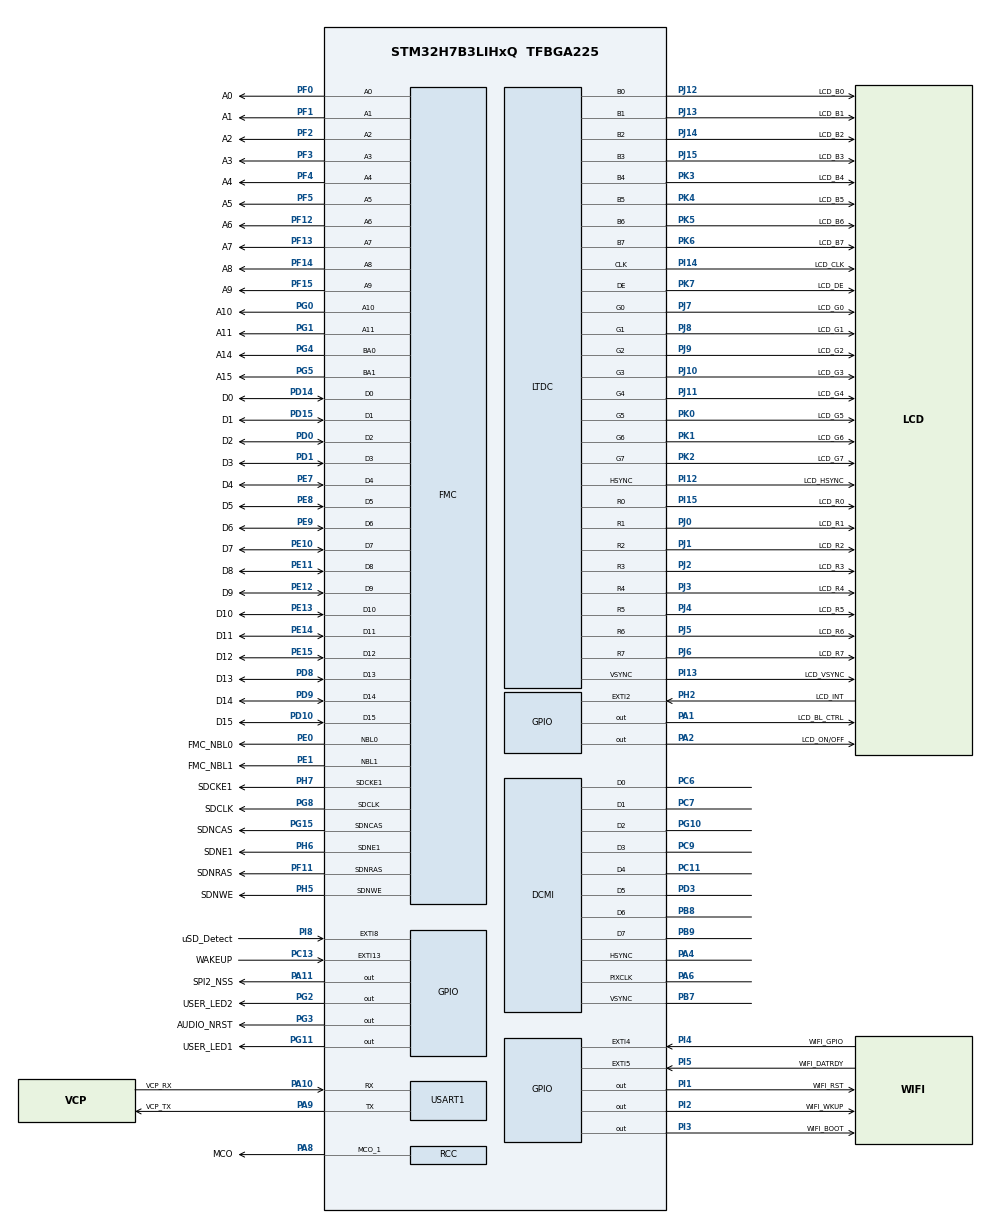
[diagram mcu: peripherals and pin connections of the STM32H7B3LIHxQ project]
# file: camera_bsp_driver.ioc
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CORTEX_M7.CPU_DCache=Enabled
CORTEX_M7.CPU_ICache=Enabled
DCMI.HSPolarity=DCMI_HSPOLARITY_HIGH
DCMI.PCKPolarity=DCMI_PCKPOLARITY_RISING
DCMI.VSPolarity=DCMI_VSPOLARITY_HIGH
DMA2D.ColorMode=DMA2D_OUTPUT_ARGB8888
DMA2D.InputColorModeForeground=DMA2D_INPUT_RGB565
DMA2D.Mode=DMA2D_M2M_PFC
Dma.DCMI.0.Direction=DMA_PERIPH_TO_MEMORY
Dma.DCMI.0.EventEnable=DISABLE
Dma.DCMI.0.FIFOMode=DMA_FIFOMODE_DISABLE
Dma.DCMI.0.Instance=DMA2_Stream1
Dma.DCMI.0.MemDataAlignment=DMA_MDATAALIGN_WORD
Dma.DCMI.0.MemInc=DMA_MINC_ENABLE
Dma.DCMI.0.Mode=DMA_NORMAL
Dma.DCMI.0.PeriphDataAlignment=DMA_PDATAALIGN_WORD
Dma.DCMI.0.PeriphInc=DMA_PINC_DISABLE
Dma.DCMI.0.Polarity=HAL_DMAMUX_REQ_GEN_RISING
Dma.DCMI.0.Priority=DMA_PRIORITY_HIGH
Dma.DCMI.0.RequestNumber=1
Dma.DCMI.0.SignalID=NONE
Dma.DCMI.0.SyncEnable=DISABLE
Dma.DCMI.0.SyncPolarity=HAL_DMAMUX_SYNC_NO_EVENT
Dma.DCMI.0.SyncRequestNumber=1
Dma.DCMI.0.SyncSignalID=NONE
Dma.Request0=DCMI
FMC.CASLatency2=FMC_SDRAM_CAS_LATENCY_2
FMC.ColumnBitsNumber2=FMC_SDRAM_COLUMN_BITS_NUM_9
FMC.ExitSelfRefreshDelay2=7
FMC.LoadToActiveDelay2=2
FMC.RCDDelay2=2
FMC.RPDelay1=2
FMC.RPDelay2=2
FMC.ReadBurst1=FMC_SDRAM_RBURST_ENABLE
FMC.ReadBurst2=FMC_SDRAM_RBURST_ENABLE
FMC.ReadPipeDelay1=FMC_SDRAM_RPIPE_DELAY_2
FMC.ReadPipeDelay2=FMC_SDRAM_RPIPE_DELAY_2
FMC.RowCycleDelay1=6
FMC.RowCycleDelay2=6
FMC.SDClockPeriod1=FMC_SDRAM_CLOCK_PERIOD_2
FMC.SDClockPeriod2=FMC_SDRAM_CLOCK_PERIOD_2
FMC.SelfRefreshTime2=5
FMC.WriteRecoveryTime2=3
LTDC.Alpha_L0=0
LTDC.Blue_L0=0
LTDC.DEPolarity=LTDC_DEPOLARITY_AH
LTDC.FBStartAdress_L0=0
LTDC.ImageHeight_L0=0
LTDC.ImageWidth_L0=0
LTDC.Layers=0
LTDC.PixelFormat_L0=LTDC_PIXEL_FORMAT_ARGB8888
LTDC.WindowX0_L0=0
LTDC.WindowX1_L0=0
LTDC.WindowY0_L0=0
LTDC.WindowY1_L0=0
Mcu.Family=STM32H7
Mcu.Name=STM32H7B3LIHxQ
Mcu.Package=TFBGA225
NVIC.DCMI_PSSI_IRQn=true\:0\:0\:false\:false\:true\:true\:true\:true
NVIC.DMA2D_IRQn=true\:0\:0\:false\:false\:true\:true\:true\:true
NVIC.DMA2_Stream1_IRQn=true\:0\:0\:false\:false\:true\:false\:true\:true
NVIC.LTDC_ER_IRQn=true\:0\:0\:false\:false\:true\:true\:true\:true
NVIC.LTDC_IRQn=true\:0\:0\:false\:false\:true\:true\:true\:true
NVIC.PriorityGroup=NVIC_PRIORITYGROUP_4
NVIC.USART1_IRQn=true\:0\:0\:false\:false\:true\:true\:true\:true
PA0.GPIO_Label=I2S6_WS
PA0.Signal=I2S6_WS
PA1.GPIO_Label=LCD_BL_CTRL
PA1.PinState=GPIO_PIN_SET
PA1.Signal=GPIO_Output
PA10.GPIO_Label=VCP_RX
PA10.Mode=Asynchronous
PA10.Signal=USART1_RX
PA11.GPIO_Label=SPI2_NSS
PA11.Signal=GPIO_Output
PA12.GPIO_Label=SPI2_SCK
PA12.Signal=SPI2_SCK
PA13.GPIO_Label=JTMS
PA13.Mode=JTAG_5_pins
PA13.Signal=DEBUG_JTMS-SWDIO
PA14.GPIO_Label=JTCK
PA14.Mode=JTAG_5_pins
PA14.Signal=DEBUG_JTCK-SWCLK
PA15.GPIO_Label=JTDI
PA15.Mode=JTAG_5_pins
PA15.Signal=DEBUG_JTDI
PA2.GPIO_Label=LCD_ON/OFF
PA2.PinState=GPIO_PIN_SET
PA2.Signal=GPIO_Output
PA3.GPIO_Label=I2S6_MCK
PA3.Signal=I2S6_MCK
PA4.Mode=Slave_8_bits_External_Synchro
PA4.Signal=DCMI_HSYNC
PA6.Mode=Slave_8_bits_External_Synchro
PA6.Signal=DCMI_PIXCLK
PA8.GPIO_Label=MCO
PA8.Mode=Clock-out-1
PA8.Signal=RCC_MCO_1
PA9.GPIO_Label=VCP_TX
PA9.Mode=Asynchronous
PA9.Signal=USART1_TX
PB2.GPIO_Label=OCSPI1_CLK
PB2.Signal=OCTOSPIM_P1_CLK
PB3.GPIO_Label=JTDO_TRACESWO
PB3.Mode=JTAG_5_pins
PB3.Signal=DEBUG_JTDO-SWO
PB4.Mode=JTAG_5_pins
PB4.Signal=DEBUG_JTRST
PB7.Mode=Slave_8_bits_External_Synchro
PB7.Signal=DCMI_VSYNC
PB8.Mode=Slave_8_bits_External_Synchro
PB8.Signal=DCMI_D6
PB9.Mode=Slave_8_bits_External_Synchro
PB9.Signal=DCMI_D7
PC1.GPIO_Label=OCSPI1_IO4
PC1.Signal=OCTOSPIM_P1_IO4
PC10.GPIO_Label=SDIO1_D2
PC10.Signal=SDMMC1_D2
PC11.Mode=Slave_8_bits_External_Synchro
PC11.Signal=DCMI_D4
PC12.GPIO_Label=SDIO1_CK
PC12.Signal=SDMMC1_CK
PC13.GPIO_Label=WAKEUP
PC13.Signal=GPXTI13
PC14-OSC32_IN.Mode=LSE-External-Oscillator
PC14-OSC32_IN.Signal=RCC_OSC32_IN
PC15-OSC32_OUT.Mode=LSE-External-Oscillator
PC15-OSC32_OUT.Signal=RCC_OSC32_OUT
PC2.GPIO_Label=SPI2_MISO
PC2.Signal=SPI2_MISO
PC3.GPIO_Label=SPI2_MOSI
PC3.Signal=SPI2_MOSI
PC5.GPIO_Label=OCSPI1_DQS
PC5.Signal=OCTOSPIM_P1_DQS
PC6.Mode=Slave_8_bits_External_Synchro
PC6.Signal=DCMI_D0
PC7.Mode=Slave_8_bits_External_Synchro
PC7.Signal=DCMI_D1
PC8.GPIO_Label=SDIO1_D0
PC8.Signal=SDMMC1_D0
PC9.Mode=Slave_8_bits_External_Synchro
PC9.Signal=DCMI_D3
PD0.GPIO_Label=D2
PD0.Signal=FMC_D2_DA2
PD1.GPIO_Label=D3
PD1.Signal=FMC_D3_DA3
PD10.GPIO_Label=D15
PD10.Signal=FMC_D15_DA15
PD12.GPIO_Label=I2C4_SCL
PD12.GPIO_Pu=GPIO_PULLUP
PD12.Signal=I2C4_SCL
PD13.GPIO_Label=I2C4_SDA
PD13.GPIO_Pu=GPIO_PULLUP
PD13.Signal=I2C4_SDA
PD14.GPIO_Label=D0
PD14.Signal=FMC_D0_DA0
PD15.GPIO_Label=D1
PD15.Signal=FMC_D1_DA1
PD2.GPIO_Label=SDIO1_CMD
PD2.Signal=SDMMC1_CMD
PD3.Mode=Slave_8_bits_External_Synchro
PD3.Signal=DCMI_D5
PD7.GPIO_Label=OCSPI1_IO7
PD7.Signal=OCTOSPIM_P1_IO7
PD8.GPIO_Label=D13
PD8.Signal=FMC_D13_DA13
PD9.GPIO_Label=D14
PD9.Signal=FMC_D14_DA14
PE0.GPIO_Label=FMC_NBL0
PE0.Signal=FMC_NBL0
PE1.GPIO_Label=FMC_NBL1
PE1.Signal=FMC_NBL1
PE10.GPIO_Label=D7
PE10.Signal=FMC_D7_DA7
PE11.GPIO_Label=D8
PE11.Signal=FMC_D8_DA8
PE12.GPIO_Label=D9
PE12.Signal=FMC_D9_DA9
PE13.GPIO_Label=D10
PE13.Signal=FMC_D10_DA10
PE14.GPIO_Label=D11
PE14.Signal=FMC_D11_DA11
PE15.GPIO_Label=D12
PE15.Signal=FMC_D12_DA12
PE7.GPIO_Label=D4
PE7.Signal=FMC_D4_DA4
PE8.GPIO_Label=D5
PE8.Signal=FMC_D5_DA5
PE9.GPIO_Label=D6
PE9.Signal=FMC_D6_DA6
PF0.GPIO_Label=A0
PF0.Signal=FMC_A0
PF1.GPIO_Label=A1
PF1.Signal=FMC_A1
PF11.GPIO_Label=SDNRAS
PF11.Signal=FMC_SDNRAS
PF12.GPIO_Label=A6
PF12.Signal=FMC_A6
PF13.GPIO_Label=A7
PF13.Signal=FMC_A7
PF14.GPIO_Label=A8
PF14.Signal=FMC_A8
PF15.GPIO_Label=A9
PF15.Signal=FMC_A9
PF2.GPIO_Label=A2
PF2.Signal=FMC_A2
PF3.GPIO_Label=A3
PF3.Signal=FMC_A3
PF4.GPIO_Label=A4
PF4.Signal=FMC_A4
PF5.GPIO_Label=A5
PF5.Signal=FMC_A5
PG0.GPIO_Label=A10
PG0.Signal=FMC_A10
PG1.GPIO_Label=A11
PG1.Signal=FMC_A11
PG10.Mode=Slave_8_bits_External_Synchro
PG10.Signal=DCMI_D2
PG11.GPIO_Label=USER_LED1
PG11.Signal=GPIO_Output
PG12.GPIO_Label=I2S6_SDI
PG12.Signal=I2S6_SDI
PG13.GPIO_Label=I2S6_CK
PG13.Signal=I2S6_CK
PG14.GPIO_Label=I2S6_SDO
PG14.Signal=I2S6_SDO
PG15.GPIO_Label=SDNCAS
PG15.Signal=FMC_SDNCAS
PG2.GPIO_Label=USER_LED2
PG2.Signal=GPIO_Output
PG3.GPIO_Label=AUDIO_NRST
PG3.PinState=GPIO_PIN_SET
PG3.Signal=GPIO_Output
PG4.GPIO_Label=A14
PG4.Signal=FMC_A14_BA0
PG5.GPIO_Label=A15
PG5.Signal=FMC_A15_BA1
PG6.GPIO_Label=OCSPI1_NCS
PG6.Signal=OCTOSPIM_P1_NCS
PG8.GPIO_Label=SDCLK
PG8.Signal=FMC_SDCLK
PG9.GPIO_Label=OCSPI1_IO6
PG9.Signal=OCTOSPIM_P1_IO6
PH0-OSC_IN.Mode=HSE-External-Oscillator
PH0-OSC_IN.Signal=RCC_OSC_IN
PH1-OSC_OUT.Mode=HSE-External-Oscillator
PH1-OSC_OUT.Signal=RCC_OSC_OUT
PH2.GPIO_Label=LCD_INT
PH2.Signal=GPXTI2
PH3.GPIO_Label=OCSPI1_IO5
PH3.Signal=OCTOSPIM_P1_IO5
PH5.GPIO_Label=SDNWE
PH5.Signal=FMC_SDNWE
PH6.GPIO_Label=SDNE1
PH6.Mode=SdramChipSelect2_2
PH6.Signal=FMC_SDNE1
PH7.GPIO_Label=SDCKE1
PH7.Mode=SdramChipSelect2_2
PH7.Signal=FMC_SDCKE1
PI1.GPIO_Label=WIFI_RST
PI1.Signal=GPIO_Output
PI12.GPIO_Label=LCD_HSYNC
PI12.GPIO_Speed=GPIO_SPEED_FREQ_VERY_HIGH
PI12.Mode=RGB888
PI12.Signal=LTDC_HSYNC
PI13.GPIO_Label=LCD_VSYNC
PI13.GPIO_Speed=GPIO_SPEED_FREQ_VERY_HIGH
PI13.Mode=RGB888
PI13.Signal=LTDC_VSYNC
PI14.GPIO_Label=LCD_CLK
PI14.GPIO_Speed=GPIO_SPEED_FREQ_VERY_HIGH
PI14.Mode=RGB888
PI14.Signal=LTDC_CLK
PI15.GPIO_Label=LCD_R0
PI15.GPIO_Speed=GPIO_SPEED_FREQ_VERY_HIGH
PI15.Mode=RGB888
PI15.Signal=LTDC_R0
PI2.GPIO_Label=WIFI_WKUP
PI2.Signal=GPIO_Output
PI3.GPIO_Label=WIFI_BOOT
PI3.Signal=GPIO_Output
PI4.GPIO_Label=WIFI_GPIO
PI4.Signal=GPXTI4
PI5.GPIO_Label=WIFI_DATRDY
PI5.Signal=GPXTI5
PI8.GPIO_Label=uSD_Detect
PI8.GPIO_PuPd=GPIO_PULLUP
PI8.Signal=GPXTI8
PJ0.GPIO_Label=LCD_R1
PJ0.GPIO_Speed=GPIO_SPEED_FREQ_VERY_HIGH
PJ0.Mode=RGB888
PJ0.Signal=LTDC_R1
PJ1.GPIO_Label=LCD_R2
PJ1.GPIO_Speed=GPIO_SPEED_FREQ_VERY_HIGH
PJ1.Mode=RGB888
PJ1.Signal=LTDC_R2
PJ10.GPIO_Label=LCD_G3
PJ10.GPIO_Speed=GPIO_SPEED_FREQ_VERY_HIGH
PJ10.Mode=RGB888
PJ10.Signal=LTDC_G3
PJ11.GPIO_Label=LCD_G4
PJ11.GPIO_Speed=GPIO_SPEED_FREQ_VERY_HIGH
PJ11.Mode=RGB888
PJ11.Signal=LTDC_G4
PJ12.GPIO_Label=LCD_B0
PJ12.GPIO_Speed=GPIO_SPEED_FREQ_VERY_HIGH
PJ12.Mode=RGB888
PJ12.Signal=LTDC_B0
PJ13.GPIO_Label=LCD_B1
PJ13.GPIO_Speed=GPIO_SPEED_FREQ_VERY_HIGH
PJ13.Mode=RGB888
PJ13.Signal=LTDC_B1
PJ14.GPIO_Label=LCD_B2
PJ14.GPIO_Speed=GPIO_SPEED_FREQ_VERY_HIGH
PJ14.Mode=RGB888
PJ14.Signal=LTDC_B2
PJ15.GPIO_Label=LCD_B3
PJ15.GPIO_Speed=GPIO_SPEED_FREQ_VERY_HIGH
PJ15.Mode=RGB888
PJ15.Signal=LTDC_B3
PJ2.GPIO_Label=LCD_R3
PJ2.GPIO_Speed=GPIO_SPEED_FREQ_VERY_HIGH
PJ2.Mode=RGB888
PJ2.Signal=LTDC_R3
PJ3.GPIO_Label=LCD_R4
PJ3.GPIO_Speed=GPIO_SPEED_FREQ_VERY_HIGH
PJ3.Mode=RGB888
PJ3.Signal=LTDC_R4
PJ4.GPIO_Label=LCD_R5
PJ4.GPIO_Speed=GPIO_SPEED_FREQ_VERY_HIGH
PJ4.Mode=RGB888
PJ4.Signal=LTDC_R5
PJ5.GPIO_Label=LCD_R6
PJ5.GPIO_Speed=GPIO_SPEED_FREQ_VERY_HIGH
PJ5.Mode=RGB888
PJ5.Signal=LTDC_R6
PJ6.GPIO_Label=LCD_R7
PJ6.GPIO_Speed=GPIO_SPEED_FREQ_VERY_HIGH
PJ6.Mode=RGB888
PJ6.Signal=LTDC_R7
PJ7.GPIO_Label=LCD_G0
PJ7.GPIO_Speed=GPIO_SPEED_FREQ_VERY_HIGH
PJ7.Mode=RGB888
PJ7.Signal=LTDC_G0
PJ8.GPIO_Label=LCD_G1
PJ8.GPIO_Speed=GPIO_SPEED_FREQ_VERY_HIGH
PJ8.Mode=RGB888
PJ8.Signal=LTDC_G1
PJ9.GPIO_Label=LCD_G2
PJ9.GPIO_Speed=GPIO_SPEED_FREQ_VERY_HIGH
PJ9.Mode=RGB888
PJ9.Signal=LTDC_G2
PK0.GPIO_Label=LCD_G5
PK0.GPIO_Speed=GPIO_SPEED_FREQ_VERY_HIGH
PK0.Mode=RGB888
PK0.Signal=LTDC_G5
PK1.GPIO_Label=LCD_G6
PK1.GPIO_Speed=GPIO_SPEED_FREQ_VERY_HIGH
PK1.Mode=RGB888
PK1.Signal=LTDC_G6
PK2.GPIO_Label=LCD_G7
PK2.GPIO_Speed=GPIO_SPEED_FREQ_VERY_HIGH
PK2.Mode=RGB888
PK2.Signal=LTDC_G7
PK3.GPIO_Label=LCD_B4
PK3.GPIO_Speed=GPIO_SPEED_FREQ_VERY_HIGH
PK3.Mode=RGB888
PK3.Signal=LTDC_B4
PK4.GPIO_Label=LCD_B5
PK4.GPIO_Speed=GPIO_SPEED_FREQ_VERY_HIGH
PK4.Mode=RGB888
PK4.Signal=LTDC_B5
PK5.GPIO_Label=LCD_B6
PK5.GPIO_Speed=GPIO_SPEED_FREQ_VERY_HIGH
PK5.Mode=RGB888
PK5.Signal=LTDC_B6
PK6.GPIO_Label=LCD_B7
PK6.GPIO_Speed=GPIO_SPEED_FREQ_VERY_HIGH
PK6.Mode=RGB888
PK6.Signal=LTDC_B7
PK7.GPIO_Label=LCD_DE
PK7.GPIO_Speed=GPIO_SPEED_FREQ_VERY_HIGH
PK7.Mode=RGB888
PK7.Signal=LTDC_DE
ProjectManager.HeapSize=0x800
ProjectManager.StackSize=0x800
ProjectManager.TargetToolchain=STM32CubeIDE
RCC.ADCFreq_Value=200000000
RCC.APB1Freq_Value=140000000
RCC.APB2Freq_Value=140000000
RCC.APB3Freq_Value=140000000
RCC.APB4Freq_Value=140000000
RCC.CDPPRE=RCC_APB3_DIV2
RCC.CDPPRE1=RCC_APB1_DIV2
RCC.CDPPRE2=RCC_APB2_DIV2
RCC.CortexFreq_Value=280000000
RCC.DIVM1=12
RCC.DIVM2=12
RCC.DIVM3=24
RCC.DIVN1=280
RCC.DIVN2=200
RCC.DIVN3=192
RCC.DIVP3=17
RCC.DIVQ1=3
RCC.DIVR1=4
RCC.DIVR3=16
RCC.FMCCLockSelection=RCC_FMCCLKSOURCE_PLL2
RCC.HCLKFreq_Value=280000000
RCC.PLL2FRACN=0
RCC.PLLSourceVirtual=RCC_PLLSOURCE_HSE
RCC.QSPICLockSelection=RCC_OSPICLKSOURCE_PLL2
RCC.RCC_MCO1Source=RCC_MCO1SOURCE_HSE
RCC.RTCClockSelection=RCC_RTCCLKSOURCE_LSE
RCC.SDMMC1CLockSelection=RCC_SDMMCCLKSOURCE_PLL2
RCC.SPI123CLockSelection=RCC_SPI123CLKSOURCE_CLKP
RCC.SRDPPRE=RCC_APB4_DIV2
RCC.SYSCLKFreq_VALUE=280000000
RCC.SYSCLKSource=RCC_SYSCLKSOURCE_PLLCLK
RCC.SupplySource=PWR_DIRECT_SMPS_SUPPLY
RCC.USBFreq_Value=186666666.66666666
SH.FMC_A0.0=FMC_A0,12b-sda2
SH.FMC_A1.0=FMC_A1,12b-sda2
SH.FMC_A10.0=FMC_A10,12b-sda2
SH.FMC_A11.0=FMC_A11,12b-sda2
SH.FMC_A14_BA0.0=FMC_BA0,FourSdramBanks2
SH.FMC_A15_BA1.0=FMC_BA1,FourSdramBanks2
SH.FMC_A2.0=FMC_A2,12b-sda2
SH.FMC_A3.0=FMC_A3,12b-sda2
SH.FMC_A4.0=FMC_A4,12b-sda2
SH.FMC_A5.0=FMC_A5,12b-sda2
SH.FMC_A6.0=FMC_A6,12b-sda2
SH.FMC_A7.0=FMC_A7,12b-sda2
SH.FMC_A8.0=FMC_A8,12b-sda2
SH.FMC_A9.0=FMC_A9,12b-sda2
SH.FMC_D0_DA0.0=FMC_D0,sd-16b-d2
SH.FMC_D10_DA10.0=FMC_D10,sd-16b-d2
SH.FMC_D11_DA11.0=FMC_D11,sd-16b-d2
SH.FMC_D12_DA12.0=FMC_D12,sd-16b-d2
SH.FMC_D13_DA13.0=FMC_D13,sd-16b-d2
SH.FMC_D14_DA14.0=FMC_D14,sd-16b-d2
SH.FMC_D15_DA15.0=FMC_D15,sd-16b-d2
SH.FMC_D1_DA1.0=FMC_D1,sd-16b-d2
SH.FMC_D2_DA2.0=FMC_D2,sd-16b-d2
SH.FMC_D3_DA3.0=FMC_D3,sd-16b-d2
SH.FMC_D4_DA4.0=FMC_D4,sd-16b-d2
SH.FMC_D5_DA5.0=FMC_D5,sd-16b-d2
SH.FMC_D6_DA6.0=FMC_D6,sd-16b-d2
SH.FMC_D7_DA7.0=FMC_D7,sd-16b-d2
SH.FMC_D8_DA8.0=FMC_D8,sd-16b-d2
SH.FMC_D9_DA9.0=FMC_D9,sd-16b-d2
SH.FMC_NBL0.0=FMC_NBL0,Sd2ByteEnable2
SH.FMC_NBL1.0=FMC_NBL1,Sd2ByteEnable2
SH.FMC_SDCLK.0=FMC_SDCLK,12b-sda2
SH.FMC_SDNCAS.0=FMC_SDNCAS,12b-sda2
SH.FMC_SDNRAS.0=FMC_SDNRAS,12b-sda2
SH.FMC_SDNWE.0=FMC_SDNWE,12b-sda2
STMicroelectronics.X-CUBE-AI.8.0.0.ActivationBufferSizeList=234704
STMicroelectronics.X-CUBE-AI.8.0.0.ActivationBuffers=pool0
STMicroelectronics.X-CUBE-AI.8.0.0.ActivationNames=pool0
STMicroelectronics.X-CUBE-AI.8.0.0.ActivationSizes=AI_FACE_DETECTION_DATA_ACTIVATION_1_SIZE
STMicroelectronics.X-CUBE-AI.8.0.0.ApplicationCcDeviceJjApplication=ApplicationTemplate
STMicroelectronics.X-CUBE-AI.8.0.0.HeapSize=0x800
STMicroelectronics.X-CUBE-AI.8.0.0.InternalRamActivationBufferMaxSize=AI_FACE_DETECTION_DATA_ACTIVATIONS_SIZE
STMicroelectronics.X-CUBE-AI.8.0.0.LatestDirectoryUsed-272fd21c94214a2785b823dab08422d9cb7c79724c26d104a3e426833abdfe55=C\:\\Users\\hubert\\STM32CubeIDE\\workspace_1.10.0\\camera_bsp_driver
STMicroelectronics.X-CUBE-AI.8.0.0.MaximumNumberOfInputLayer=1
STMicroelectronics.X-CUBE-AI.8.0.0.MaximumNumberOfOutputLayer=1
STMicroelectronics.X-CUBE-AI.8.0.0.MaximumSizeOfInputLayer=1
STMicroelectronics.X-CUBE-AI.8.0.0.MaximumSizeOfOutputLayer=1
STMicroelectronics.X-CUBE-AI.8.0.0.ModelActualCompression-272fd21c94214a2785b823dab08422d9cb7c79724c26d104a3e426833abdfe55=0.0
STMicroelectronics.X-CUBE-AI.8.0.0.ModelCompression-272fd21c94214a2785b823dab08422d9cb7c79724c26d104a3e426833abdfe55=None
STMicroelectronics.X-CUBE-AI.8.0.0.ModelFlashOccupation-272fd21c94214a2785b823dab08422d9cb7c79724c26d104a3e426833abdfe55=550922
STMicroelectronics.X-CUBE-AI.8.0.0.ModelHashList=272fd21c94214a2785b823dab08422d9cb7c79724c26d104a3e426833abdfe55
STMicroelectronics.X-CUBE-AI.8.0.0.ModelKind-272fd21c94214a2785b823dab08422d9cb7c79724c26d104a3e426833abdfe55=TFLITE
STMicroelectronics.X-CUBE-AI.8.0.0.ModelMacc-272fd21c94214a2785b823dab08422d9cb7c79724c26d104a3e426833abdfe55=40573698
STMicroelectronics.X-CUBE-AI.8.0.0.ModelName-272fd21c94214a2785b823dab08422d9cb7c79724c26d104a3e426833abdfe55=face_detection
STMicroelectronics.X-CUBE-AI.8.0.0.ModelNameList=face_detection
STMicroelectronics.X-CUBE-AI.8.0.0.ModelRamOccupation-272fd21c94214a2785b823dab08422d9cb7c79724c26d104a3e426833abdfe55=234704
STMicroelectronics.X-CUBE-AI.8.0.0.ModelStructureFile-272fd21c94214a2785b823dab08422d9cb7c79724c26d104a3e426833abdfe55=quantized_model_122it.tflite
STMicroelectronics.X-CUBE-AI.8.0.0.ModelType-272fd21c94214a2785b823dab08422d9cb7c79724c26d104a3e426833abdfe55=STM32Cube.AI runtime
STMicroelectronics.X-CUBE-AI.8.0.0.ReadyForCodeGeneration=true
STMicroelectronics.X-CUBE-AI.8.0.0.StackSize=0x800
STMicroelectronics.X-CUBE-AI.8.0.0.WorkingBufferStartAddrList=0xFFFFFFFF
STMicroelectronics.X-CUBE-AI.8.0.0.XAaCUBEAaAICcArtificialOoIntelligenceJjCore=true
STMicroelectronics.X-CUBE-AI.8.0.0.copyWeightToRam=false
STMicroelectronics.X-CUBE-AI.8.0.0.copyWeightToRam-272fd21c94214a2785b823dab08422d9cb7c79724c26d104a3e426833abdfe55=false
STMicroelectronics.X-CUBE-AI.8.0.0.customLayerConfigEnabled=false
STMicroelectronics.X-CUBE-AI.8.0.0.customLayerConfigEnabled-272fd21c94214a2785b823dab08422d9cb7c79724c26d104a3e426833abdfe55=false
STMicroelectronics.X-CUBE-AI.8.0.0.useInputAllocation=true
STMicroelectronics.X-CUBE-AI.8.0.0.useInputAllocation-272fd21c94214a2785b823dab08422d9cb7c79724c26d104a3e426833abdfe55=true
STMicroelectronics.X-CUBE-AI.8.0.0.useOutputAllocation=true
STMicroelectronics.X-CUBE-AI.8.0.0.useOutputAllocation-272fd21c94214a2785b823dab08422d9cb7c79724c26d104a3e426833abdfe55=true
USART1.VirtualMode-Asynchronous=VM_ASYNC
VP_CRC_VS_CRC.Mode=CRC_Activate
VP_DMA2D_VS_DMA2D.Mode=DMA2D_Activate
VP_RTC_VS_RTC_Activate.Mode=RTC_Enabled
VP_STMicroelectronics.X-CUBE-AI_VS_ArtificialOoIntelligenceJjXAaCUBEAaAI_8.0.0.Mode=ArtificialOoIntelligenceJjXAaCUBEAaAI
VP_STMicroelectronics.X-CUBE-AI_VS_DeviceJjApplication_8.0.0.Mode=DeviceJjApplication
board=STM32H7B3I-DK

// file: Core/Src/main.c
/* USER CODE BEGIN Header */
/**
 ******************************************************************************
 * @file           : main.c
 * @brief          : Main program body
 ******************************************************************************
 * @attention
 *
 * Copyright (c) 2023 STMicroelectronics.
 * All rights reserved.
 *
 * This software is licensed under terms that can be found in the LICENSE file
 * in the root directory of this software component.
 * If no LICENSE file comes with this software, it is provided AS-IS.
 *
 ******************************************************************************
 */
/* USER CODE END Header */
#include "main.h"
#include "crc.h"
#include "dcmi.h"
#include "dma.h"
#include "dma2d.h"
#include "ltdc.h"
#include "rtc.h"
#include "usart.h"
#include "gpio.h"
#include "fmc.h"
#include "app_x-cube-ai.h"

/* USER CODE BEGIN Includes */
#include "retarget.h"
#include <stdio.h>
#include <string.h>
#include <img_utils.h>
#include <process.h>
/* USER CODE END Includes */

/* USER CODE BEGIN PV */
#define OV5640_address 0x78

__IO uint32_t camera_frame_ready = 0;

float probabilites[GRID_SIZE*GRID_SIZE*2] = {
		1,1,1,1,1,1,1,1,1,1,1,1,0,0,0,0,0,0,0,0,0,0,0,0,
	     1,1,1,1,1,1,1,1,1,1,1,1,0,0,0,0,0,0,0,0,0,0,0,0,
	     1,1,1,1,1,1,1,1,1,1,1,1,0,0,0,0,0,0,0,0,0,0,0,0,
	     1,1,1,1,1,1,1,1,1,1,1,1,0,0,0,0,0,0,0,0,0,0,0,0,
	     1,1,1,1,1,1,1,1,1,1,1,1,0,0,0,0,0,0,0,0,0,0,0,0,
	     1,1,1,1,1,1,1,1,1,1,1,1,0,0,0,0,0,0,0,0,0,0,0,0,
		 0,0,0,0,0,0,0,0,0,0,0,0,1,1,1,1,1,1,1,1,1,1,1,1,
		 0,0,0,0,0,0,0,0,0,0,0,0,1,1,1,1,1,1,1,1,1,1,1,1,
		 0,0,0,0,0,0,0,0,0,0,0,0,1,1,1,1,1,1,1,1,1,1,1,1,
		 0,0,0,0,0,0,0,0,0,0,0,0,1,1,1,1,1,1,1,1,1,1,1,1,
		 0,0,0,0,0,0,0,0,0,0,0,0,1,1,1,1,1,1,1,1,1,1,1,1,
		 0,0,0,0,0,0,0,0,0,0,0,0,1,1,1,1,1,1,1,1,1,1,1,1,

};

uint32_t rescaledImg[RESCALED_IMG*RESCALED_IMG];
/* USER CODE END PV */

void SystemClock_Config(void);

int main(void)
{

  /* Enable I-Cache---------------------------------------------------------*/
  SCB_EnableICache();

  /* Enable D-Cache---------------------------------------------------------*/
  SCB_EnableDCache();

  /* MCU Configuration--------------------------------------------------------*/

  /* Reset of all peripherals, Initializes the Flash interface and the Systick. */
  HAL_Init();

  /* Configure the system clock */
  SystemClock_Config();

  /* Initialize all configured peripherals */
  MX_GPIO_Init();
  MX_DMA_Init();
  MX_USART1_UART_Init();
  MX_DMA2D_Init();
  MX_LTDC_Init();
  MX_DCMI_Init();
  MX_RTC_Init();
  MX_FMC_Init();
  MX_CRC_Init();
  MX_X_CUBE_AI_Init();
  /* USER CODE BEGIN 2 */
    RetargetInit(&huart1);
    BSP_CAMERA_PwrDown(0);
    if (BSP_CAMERA_Init(0, CAMERA_R480x272, CAMERA_PF_RGB565) !=
        BSP_ERROR_NONE) {
        Error_Handler();
    }
    HAL_Delay(1000);
    //  buffer[5460] = 255;
    LTDC_Init_from_buffer((uint32_t *)LCD_BUFFER);

  /* USER CODE END 2 */

  /* Infinite loop */
  /* USER CODE BEGIN WHILE */

    while (1) {
    	// make photo
        BSP_CAMERA_Start(0, (uint8_t *)CAMERA_BUFFER, CAMERA_MODE_SNAPSHOT);
        while (camera_frame_ready == 0) {
        };
        BSP_CAMERA_Stop(0);
        // process photo
        DMA2D_Convert((uint8_t *)CAMERA_BUFFER, (uint32_t *)LCD_BUFFER);

        // rescale
        rescaleImage((uint32_t*)LCD_BUFFER, (uint32_t*)rescaledImg, LTDC_WIDTH, LTDC_HEIGHT, RESCALED_IMG, RESCALED_IMG);

    /* USER CODE END WHILE */

//  MX_X_CUBE_AI_Process();
    /* USER CODE BEGIN 3 */
//        uint32_t *lcd_ptr = (uint32_t *)LCD_BUFFER;
//        uint32_t table[480*272]={0};
//        for (int i = 0; i < 480*272; i++) {
//            table[i] = *(lcd_ptr+i);
//        }
//        printf("image print start");
//        for(uint64_t i = 0; i<LTDC_WIDTH*LTDC_HEIGHT; i++){
//        	printf("%u, %u, %u,", (uint8_t)((*(lcd_ptr+i)&0xff0000)>>16), (uint8_t)((*(lcd_ptr+i)&0xff00)>>8), (uint8_t)(*(lcd_ptr+i)&0xff));
//        }
//        printf("end image");
        MX_X_CUBE_AI_Process((uint32_t *)LCD_BUFFER, (uint32_t*)rescaledImg);
  	  	//postProcess((uint32_t *)LCD_BUFFER, LTDC_WIDTH, LTDC_HEIGHT, 96, 96, GRID_SIZE, probabilites);

        HAL_GPIO_TogglePin(USER_LED1_GPIO_Port, USER_LED1_Pin);
    }
  /* USER CODE END 3 */
}

void SystemClock_Config(void)
{
  RCC_OscInitTypeDef RCC_OscInitStruct = {0};
  RCC_ClkInitTypeDef RCC_ClkInitStruct = {0};

  /*AXI clock gating */
  RCC->CKGAENR = 0xFFFFFFFF;

  /** Supply configuration update enable
  */
  HAL_PWREx_ConfigSupply(PWR_DIRECT_SMPS_SUPPLY);

  /** Configure the main internal regulator output voltage
  */
  __HAL_PWR_VOLTAGESCALING_CONFIG(PWR_REGULATOR_VOLTAGE_SCALE0);

  while(!__HAL_PWR_GET_FLAG(PWR_FLAG_VOSRDY)) {}

  /** Configure LSE Drive Capability
  */
  HAL_PWR_EnableBkUpAccess();
  __HAL_RCC_LSEDRIVE_CONFIG(RCC_LSEDRIVE_LOW);

  /** Initializes the RCC Oscillators according to the specified parameters
  * in the RCC_OscInitTypeDef structure.
  */
  RCC_OscInitStruct.OscillatorType = RCC_OSCILLATORTYPE_HSE|RCC_OSCILLATORTYPE_LSE;
  RCC_OscInitStruct.HSEState = RCC_HSE_ON;
  RCC_OscInitStruct.LSEState = RCC_LSE_ON;
  RCC_OscInitStruct.PLL.PLLState = RCC_PLL_ON;
  RCC_OscInitStruct.PLL.PLLSource = RCC_PLLSOURCE_HSE;
  RCC_OscInitStruct.PLL.PLLM = 12;
  RCC_OscInitStruct.PLL.PLLN = 280;
  RCC_OscInitStruct.PLL.PLLP = 2;
  RCC_OscInitStruct.PLL.PLLQ = 3;
  RCC_OscInitStruct.PLL.PLLR = 4;
  RCC_OscInitStruct.PLL.PLLRGE = RCC_PLL1VCIRANGE_1;
  RCC_OscInitStruct.PLL.PLLVCOSEL = RCC_PLL1VCOWIDE;
  RCC_OscInitStruct.PLL.PLLFRACN = 0;
  if (HAL_RCC_OscConfig(&RCC_OscInitStruct) != HAL_OK)
  {
    Error_Handler();
  }

  /** Initializes the CPU, AHB and APB buses clocks
  */
  RCC_ClkInitStruct.ClockType = RCC_CLOCKTYPE_HCLK|RCC_CLOCKTYPE_SYSCLK
                              |RCC_CLOCKTYPE_PCLK1|RCC_CLOCKTYPE_PCLK2
                              |RCC_CLOCKTYPE_D3PCLK1|RCC_CLOCKTYPE_D1PCLK1;
  RCC_ClkInitStruct.SYSCLKSource = RCC_SYSCLKSOURCE_PLLCLK;
  RCC_ClkInitStruct.SYSCLKDivider = RCC_SYSCLK_DIV1;
  RCC_ClkInitStruct.AHBCLKDivider = RCC_HCLK_DIV1;
  RCC_ClkInitStruct.APB3CLKDivider = RCC_APB3_DIV2;
  RCC_ClkInitStruct.APB1CLKDivider = RCC_APB1_DIV2;
  RCC_ClkInitStruct.APB2CLKDivider = RCC_APB2_DIV2;
  RCC_ClkInitStruct.APB4CLKDivider = RCC_APB4_DIV2;

  if (HAL_RCC_ClockConfig(&RCC_ClkInitStruct, FLASH_LATENCY_7) != HAL_OK)
  {
    Error_Handler();
  }
  HAL_RCC_MCOConfig(RCC_MCO1, RCC_MCO1SOURCE_HSE, RCC_MCODIV_1);
}

/* USER CODE BEGIN 4 */

void BSP_CAMERA_FrameEventCallback(uint32_t Instance) {
    camera_frame_ready = 1;
}

/* USER CODE END 4 */

void Error_Handler(void)
{
  /* USER CODE BEGIN Error_Handler_Debug */
    /* User can add his own implementation to report the HAL error return state
     */
    __disable_irq();
    while (1) {
    }
  /* USER CODE END Error_Handler_Debug */
}

#ifdef  USE_FULL_ASSERT
/**
  * @brief  Reports the name of the source file and the source line number
  *         where the assert_param error has occurred.
  * @param  file: pointer to the source file name
  * @param  line: assert_param error line source number
  * @retval None
  */
void assert_failed(uint8_t *file, uint32_t line)
{
  /* USER CODE BEGIN 6 */
    /* User can add his own implementation to report the file name and line
       number, ex: printf("Wrong parameters value: file %s on line %d\r\n",
       file, line) */
  /* USER CODE END 6 */
}
#endif /* USE_FULL_ASSERT */
